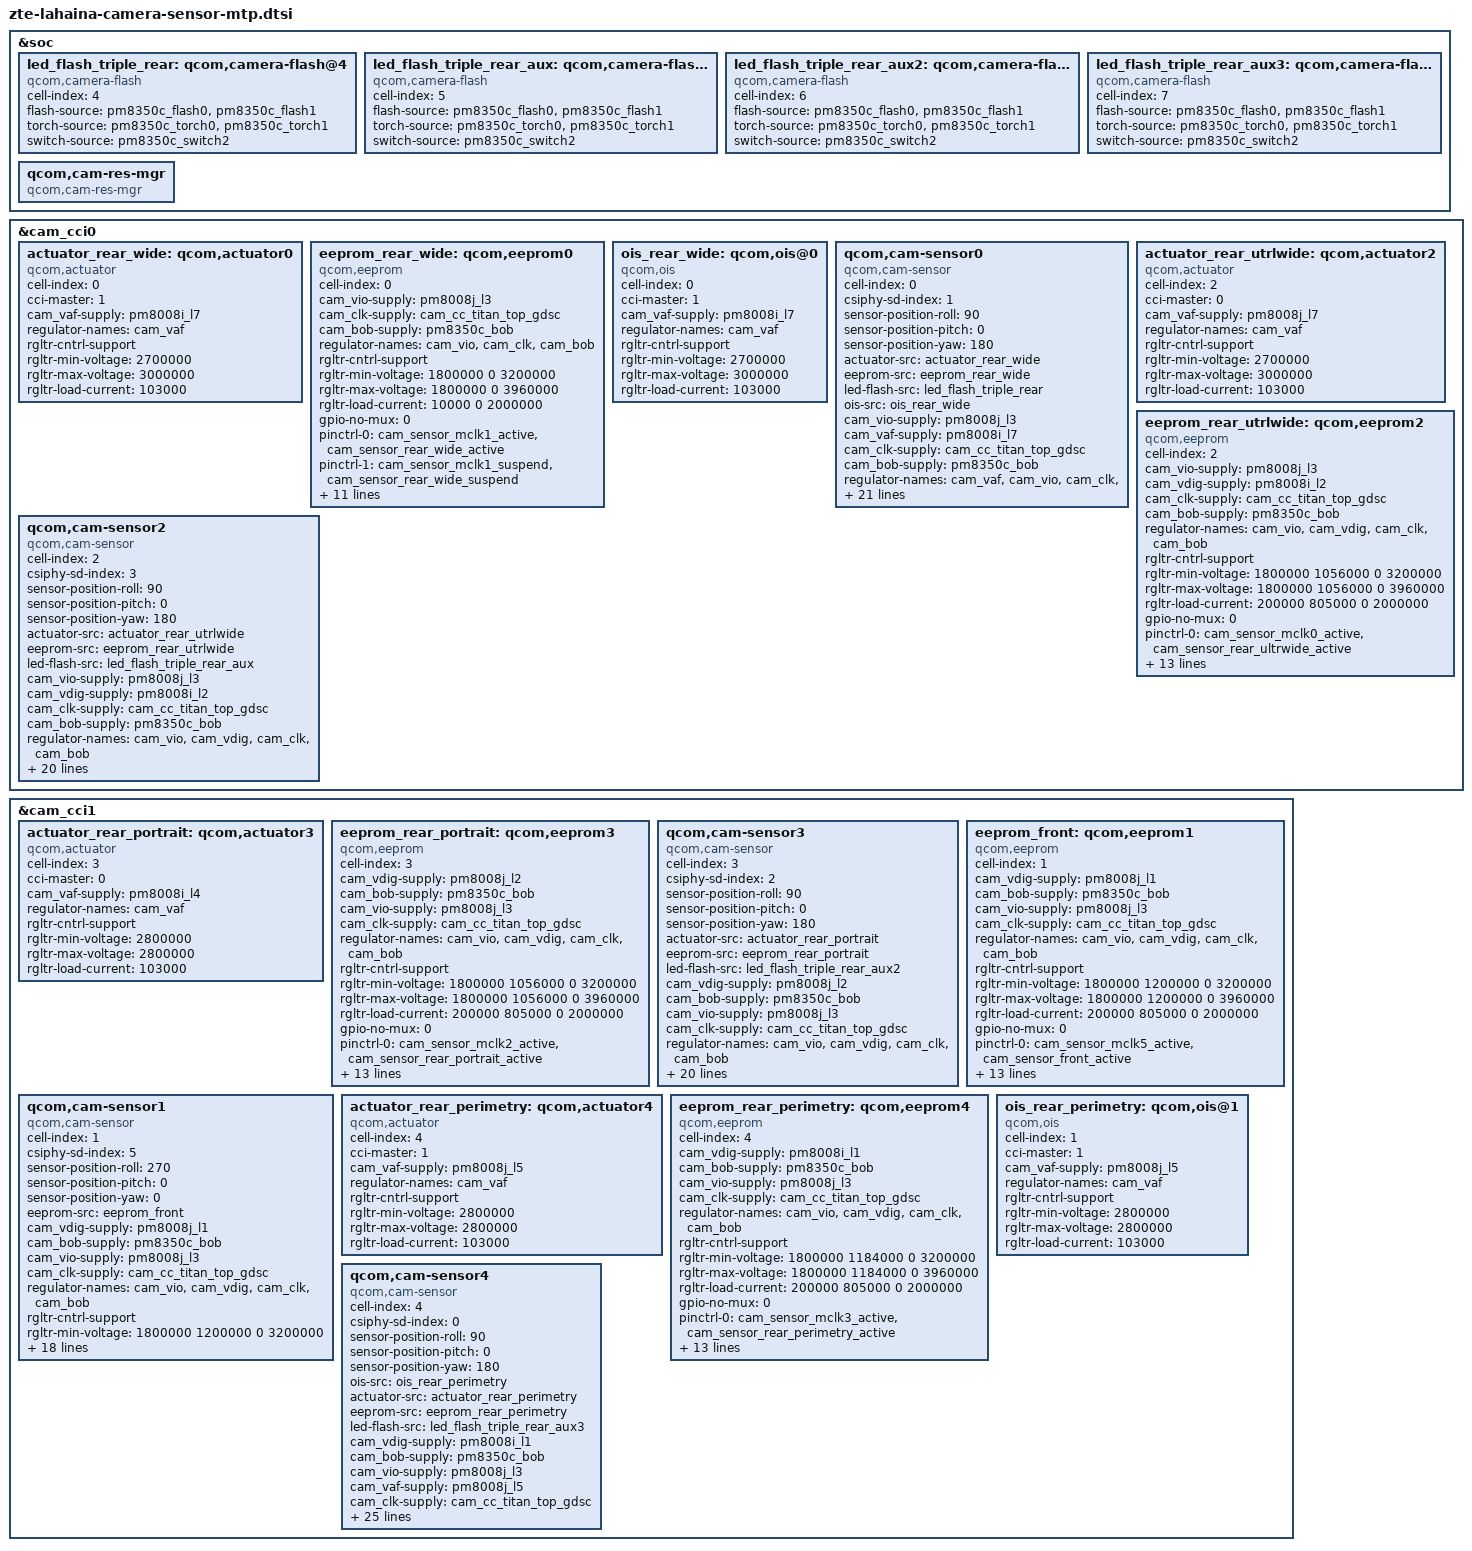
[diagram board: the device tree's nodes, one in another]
#include <dt-bindings/clock/qcom,camcc-lahaina.h>

&soc {
	led_flash_triple_rear: qcom,camera-flash@4 {
		cell-index = <4>;
		compatible = "qcom,camera-flash";
		flash-source = <&pm8350c_flash0 &pm8350c_flash1>;
		torch-source = <&pm8350c_torch0 &pm8350c_torch1>;
		switch-source = <&pm8350c_switch2>;
		status = "ok";
	};

	led_flash_triple_rear_aux: qcom,camera-flash@5 {
		cell-index = <5>;
		compatible = "qcom,camera-flash";
		flash-source = <&pm8350c_flash0 &pm8350c_flash1>;
		torch-source = <&pm8350c_torch0 &pm8350c_torch1>;
		switch-source = <&pm8350c_switch2>;
		status = "ok";
	};

	led_flash_triple_rear_aux2: qcom,camera-flash@6 {
		cell-index = <6>;
		compatible = "qcom,camera-flash";
		flash-source = <&pm8350c_flash0 &pm8350c_flash1>;
		torch-source = <&pm8350c_torch0 &pm8350c_torch1>;
		switch-source = <&pm8350c_switch2>;
		status = "ok";
	};

	led_flash_triple_rear_aux3: qcom,camera-flash@7 {
		cell-index = <7>;
		compatible = "qcom,camera-flash";
		flash-source = <&pm8350c_flash0 &pm8350c_flash1>;
		torch-source = <&pm8350c_torch0 &pm8350c_torch1>;
		switch-source = <&pm8350c_switch2>;
		status = "ok";
	};

	qcom,cam-res-mgr {
		compatible = "qcom,cam-res-mgr";
		status = "ok";
	};
};

&cam_cci0 {
	actuator_rear_wide: qcom,actuator0 {
		cell-index = <0>;
		compatible = "qcom,actuator";
		cci-master = <1>;
		cam_vaf-supply = <&pm8008i_l7>;
		regulator-names = "cam_vaf";
		rgltr-cntrl-support;
		rgltr-min-voltage = <2700000>;
		rgltr-max-voltage = <3000000>;
		rgltr-load-current = <103000>;
	};

	eeprom_rear_wide: qcom,eeprom0 {
		cell-index = <0>;
		compatible = "qcom,eeprom";
		cam_vio-supply = <&pm8008j_l3>;
		cam_clk-supply = <&cam_cc_titan_top_gdsc>;
		cam_bob-supply = <&pm8350c_bob>;
		regulator-names = "cam_vio", "cam_clk", "cam_bob";
		rgltr-cntrl-support;
		rgltr-min-voltage = <1800000 0 3200000>;
		rgltr-max-voltage = <1800000 0 3960000>;
		rgltr-load-current = <10000 0 2000000>;
		gpio-no-mux = <0>;
		pinctrl-names = "cam_default", "cam_suspend";
		pinctrl-0 = <&cam_sensor_mclk1_active
				 &cam_sensor_rear_wide_active>;
		pinctrl-1 = <&cam_sensor_mclk1_suspend
				 &cam_sensor_rear_wide_suspend>;
		gpios = <&tlmm 101 0>,
			<&tlmm 16 0>,
			<&tlmm 124 0>;
		gpio-reset = <1>;
		gpio-custom1 = <2>;
		gpio-req-tbl-num = <0 1 2>;
		gpio-req-tbl-flags = <1 0 0>;
		gpio-req-tbl-label = "CAMIF_MCLK1",
					"CAM_RESET0",
					"CAM_AVDD0";
		cci-master = <1>;
		status = "ok";
		clocks = <&clock_camcc CAM_CC_MCLK1_CLK>;
		clock-names = "cam_clk";
		clock-cntl-level = "nominal";
		clock-rates = <24000000>;
	};

	ois_rear_wide: qcom,ois@0 {
		cell-index = <0>;
		compatible = "qcom,ois";
		cci-master = <1>;
		cam_vaf-supply = <&pm8008i_l7>;
		regulator-names = "cam_vaf";
		rgltr-cntrl-support;
		rgltr-min-voltage = <2700000>;
		rgltr-max-voltage = <3000000>;
		rgltr-load-current = <103000>;
	};

	qcom,cam-sensor0 {
		cell-index = <0>;
		compatible = "qcom,cam-sensor";
		csiphy-sd-index = <1>;
		sensor-position-roll = <90>;
		sensor-position-pitch = <0>;
		sensor-position-yaw = <180>;
		actuator-src = <&actuator_rear_wide>;
		eeprom-src = <&eeprom_rear_wide>;
		led-flash-src = <&led_flash_triple_rear>;
		ois-src = <&ois_rear_wide>;
		cam_vio-supply = <&pm8008j_l3>;
		cam_vaf-supply = <&pm8008i_l7>;
		cam_clk-supply = <&cam_cc_titan_top_gdsc>;
		cam_bob-supply = <&pm8350c_bob>;
		regulator-names = "cam_vaf", "cam_vio", "cam_clk",
			"cam_bob";
		rgltr-cntrl-support;
		rgltr-min-voltage = <2700000 1800000 0 3200000>;
		rgltr-max-voltage = <3000000 1800000 0 3960000>;
		rgltr-load-current = <103000 10000 0 2000000>;
		gpio-no-mux = <0>;
		pinctrl-names = "cam_default", "cam_suspend";
		pinctrl-0 = <&cam_sensor_mclk1_active
				&cam_sensor_rear_wide_active>;
		pinctrl-1 = <&cam_sensor_mclk1_suspend
				&cam_sensor_rear_wide_suspend>;
		gpios = <&tlmm 101 0>,
			<&tlmm 16 0>,
			<&tlmm 124 0>;
		gpio-reset = <1>;
		gpio-custom1 = <2>;
		gpio-req-tbl-num = <0 1 2>;
		gpio-req-tbl-flags = <1 0 0>;
		gpio-req-tbl-label = "CAMIF_MCLK1",
					"CAM_RESET0",
					"CAM_AVDD0";
		cci-master = <1>;
		status = "ok";
		clocks = <&clock_camcc CAM_CC_MCLK1_CLK>;
		clock-names = "cam_clk";
		clock-cntl-level = "nominal";
		clock-rates = <24000000>;
	};

	actuator_rear_utrlwide: qcom,actuator2 {
		cell-index = <2>;
		compatible = "qcom,actuator";
		cci-master = <0>;
		cam_vaf-supply = <&pm8008j_l7>;
		regulator-names = "cam_vaf";
		rgltr-cntrl-support;
		rgltr-min-voltage = <2700000>;
		rgltr-max-voltage = <3000000>;
		rgltr-load-current = <103000>;
	};

	eeprom_rear_utrlwide: qcom,eeprom2 {
		cell-index = <2>;
		compatible = "qcom,eeprom";
		cam_vio-supply = <&pm8008j_l3>;
		cam_vdig-supply = <&pm8008i_l2>;
		cam_clk-supply = <&cam_cc_titan_top_gdsc>;
		cam_bob-supply = <&pm8350c_bob>;
		regulator-names = "cam_vio", "cam_vdig", "cam_clk",
			"cam_bob";
		rgltr-cntrl-support;
		rgltr-min-voltage = <1800000 1056000 0 3200000>;
		rgltr-max-voltage = <1800000 1056000 0 3960000>;
		rgltr-load-current = <200000 805000 0 2000000>;
		gpio-no-mux = <0>;
		pinctrl-names = "cam_default", "cam_suspend";
		pinctrl-0 = <&cam_sensor_mclk0_active
				 &cam_sensor_rear_ultrwide_active>;
		pinctrl-1 = <&cam_sensor_mclk0_suspend
				 &cam_sensor_rear_ultrwide_suspend>;
		gpios = <&tlmm 100 0>,
			<&tlmm 17 0>,
			<&tlmm 27 0>;
		gpio-reset = <1>;
		gpio-custom1 = <2>;
		gpio-req-tbl-num = <0 1 2>;
		gpio-req-tbl-flags = <1 0 0>;
		gpio-req-tbl-label = "CAMIF_MCLK1",
					"CAM_RESET2",
					"CAM_AVDD2";
		cci-master = <0>;
		status = "ok";
		clocks = <&clock_camcc CAM_CC_MCLK0_CLK>;
		clock-names = "cam_clk";
		clock-cntl-level = "nominal";
		clock-rates = <24000000>;
	};

	qcom,cam-sensor2 {
		cell-index = <2>;
		compatible = "qcom,cam-sensor";
		csiphy-sd-index = <3>;
		sensor-position-roll = <90>;
		sensor-position-pitch = <0>;
		sensor-position-yaw = <180>;
		actuator-src = <&actuator_rear_utrlwide>;
		eeprom-src = <&eeprom_rear_utrlwide>;
		led-flash-src = <&led_flash_triple_rear_aux>;
		cam_vio-supply = <&pm8008j_l3>;
		cam_vdig-supply = <&pm8008i_l2>;
		cam_clk-supply = <&cam_cc_titan_top_gdsc>;
		cam_bob-supply = <&pm8350c_bob>;
		regulator-names = "cam_vio", "cam_vdig", "cam_clk",
			"cam_bob";
		rgltr-cntrl-support;
		rgltr-min-voltage = <1800000 1056000 0 3200000>;
		rgltr-max-voltage = <1800000 1056000 0 3960000>;
		rgltr-load-current = <200000 805000 0 2000000>;
		gpio-no-mux = <0>;
		pinctrl-names = "cam_default", "cam_suspend";
		pinctrl-0 = <&cam_sensor_mclk0_active
				 &cam_sensor_rear_ultrwide_active>;
		pinctrl-1 = <&cam_sensor_mclk0_suspend
				 &cam_sensor_rear_ultrwide_suspend>;
		gpios = <&tlmm 100 0>,
			<&tlmm 17 0>,
			<&tlmm 27 0>;
		gpio-reset = <1>;
		gpio-custom1 = <2>;
		gpio-req-tbl-num = <0 1 2>;
		gpio-req-tbl-flags = <1 0 0>;
		gpio-req-tbl-label = "CAMIF_MCLK1",
					"CAM_RESET2",
					"CAM_AVDD2";
		cci-master = <0>;
		status = "ok";
		clocks = <&clock_camcc CAM_CC_MCLK0_CLK>;
		clock-names = "cam_clk";
		clock-cntl-level = "nominal";
		clock-rates = <24000000>;
	};
};

&cam_cci1 {
	actuator_rear_portrait: qcom,actuator3 {
		cell-index = <3>;
		compatible = "qcom,actuator";
		cci-master = <0>;
		cam_vaf-supply = <&pm8008i_l4>;
		regulator-names = "cam_vaf";
		rgltr-cntrl-support;
		rgltr-min-voltage = <2800000>;
		rgltr-max-voltage = <2800000>;
		rgltr-load-current = <103000>;
	};

	eeprom_rear_portrait: qcom,eeprom3 {
		cell-index = <3>;
		compatible = "qcom,eeprom";
		cam_vdig-supply = <&pm8008j_l2>;
		cam_bob-supply = <&pm8350c_bob>;
		cam_vio-supply = <&pm8008j_l3>;
		cam_clk-supply = <&cam_cc_titan_top_gdsc>;
		regulator-names = "cam_vio", "cam_vdig", "cam_clk",
			"cam_bob";
		rgltr-cntrl-support;
		rgltr-min-voltage = <1800000 1056000 0 3200000>;
		rgltr-max-voltage = <1800000 1056000 0 3960000>;
		rgltr-load-current = <200000 805000 0 2000000>;
		gpio-no-mux = <0>;
		pinctrl-names = "cam_default", "cam_suspend";
		pinctrl-0 = <&cam_sensor_mclk2_active
			&cam_sensor_rear_portrait_active>;
		pinctrl-1 = <&cam_sensor_mclk2_suspend
			&cam_sensor_rear_portrait_suspend>;
		gpios = <&tlmm 102 0>,
			<&tlmm 106 0>,
			<&tlmm 131 0>;
		gpio-reset = <1>;
		gpio-custom1 = <2>;
		gpio-req-tbl-num = <0 1 2>;
		gpio-req-tbl-flags = <1 0 0>;
		gpio-req-tbl-label = "CAMIF_MCLK2",
					"CAM_RESET3",
					"CAM_AVDD3";
		cci-master = <0>;
		status = "ok";
		clocks = <&clock_camcc CAM_CC_MCLK2_CLK>;
		clock-names = "cam_clk";
		clock-cntl-level = "nominal";
		clock-rates = <24000000>;
	};

	qcom,cam-sensor3 {
		cell-index = <3>;
		compatible = "qcom,cam-sensor";
		csiphy-sd-index = <2>;
		sensor-position-roll = <90>;
		sensor-position-pitch = <0>;
		sensor-position-yaw = <180>;
		actuator-src = <&actuator_rear_portrait>;
		eeprom-src = <&eeprom_rear_portrait>;
		led-flash-src = <&led_flash_triple_rear_aux2>;
		cam_vdig-supply = <&pm8008j_l2>;
		cam_bob-supply = <&pm8350c_bob>;
		cam_vio-supply = <&pm8008j_l3>;
		cam_clk-supply = <&cam_cc_titan_top_gdsc>;
		regulator-names = "cam_vio", "cam_vdig",
			"cam_clk", "cam_bob";
		rgltr-cntrl-support;
		rgltr-min-voltage = <1800000 1056000 0 3200000>;
		rgltr-max-voltage = <1800000 1056000 0 3960000>;
		rgltr-load-current = <200000 805000 0 2000000>;
		gpio-no-mux = <0>;
		pinctrl-names = "cam_default", "cam_suspend";
		pinctrl-0 = <&cam_sensor_mclk2_active
				 &cam_sensor_rear_portrait_active>;
		pinctrl-1 = <&cam_sensor_mclk2_suspend
				 &cam_sensor_rear_portrait_suspend>;
		gpios = <&tlmm 102 0>,
			<&tlmm 106 0>,
			<&tlmm 131 0>;
		gpio-reset = <1>;
		gpio-custom1 = <2>;
		gpio-req-tbl-num = <0 1 2>;
		gpio-req-tbl-flags = <1 0 0>;
		gpio-req-tbl-label = "CAMIF_MCLK2",
					"CAM_RESET3",
					"CAM_AVDD3";
		cci-master = <0>;
		status = "ok";
		clocks = <&clock_camcc CAM_CC_MCLK2_CLK>;
		clock-names = "cam_clk";
		clock-cntl-level = "nominal";
		clock-rates = <24000000>;
	};

	eeprom_front: qcom,eeprom1 {
		cell-index = <1>;
		compatible = "qcom,eeprom";
		cam_vdig-supply = <&pm8008j_l1>;
		cam_bob-supply = <&pm8350c_bob>;
		cam_vio-supply = <&pm8008j_l3>;
		cam_clk-supply = <&cam_cc_titan_top_gdsc>;
		regulator-names = "cam_vio", "cam_vdig", "cam_clk",
			"cam_bob";
		rgltr-cntrl-support;
		rgltr-min-voltage = <1800000 1200000 0 3200000>;
		rgltr-max-voltage = <1800000 1200000 0 3960000>;
		rgltr-load-current = <200000 805000 0 2000000>;
		gpio-no-mux = <0>;
		pinctrl-names = "cam_default", "cam_suspend";
		pinctrl-0 = <&cam_sensor_mclk5_active
				 &cam_sensor_front_active>;
		pinctrl-1 = <&cam_sensor_mclk5_suspend
				 &cam_sensor_front_suspend>;
		gpios = <&tlmm 105 0>,
			<&tlmm 115 0>,
			<&tlmm 123 0>;
		gpio-reset = <1>;
		gpio-custom1 = <2>;
		gpio-req-tbl-num = <0 1 2>;
		gpio-req-tbl-flags = <1 0 0>;
		gpio-req-tbl-label = "CAMIF_MCLK5",
					"CAM_RESET1",
					"CAM_AVDD1";
		cci-master = <1>;
		status = "ok";
		clocks = <&clock_camcc CAM_CC_MCLK5_CLK>;
		clock-names = "cam_clk";
		clock-cntl-level = "nominal";
		clock-rates = <24000000>;
	};

	qcom,cam-sensor1 {
		cell-index = <1>;
		compatible = "qcom,cam-sensor";
		csiphy-sd-index = <5>;
		sensor-position-roll = <270>;
		sensor-position-pitch = <0>;
		sensor-position-yaw = <0>;
		eeprom-src = <&eeprom_front>;
		cam_vdig-supply = <&pm8008j_l1>;
		cam_bob-supply = <&pm8350c_bob>;
		cam_vio-supply = <&pm8008j_l3>;
		cam_clk-supply = <&cam_cc_titan_top_gdsc>;
		regulator-names = "cam_vio", "cam_vdig", "cam_clk",
			"cam_bob";
		rgltr-cntrl-support;
		rgltr-min-voltage = <1800000 1200000 0 3200000>;
		rgltr-max-voltage = <1800000 1200000 0 3960000>;
		rgltr-load-current = <200000 805000 0 2000000>;
		gpio-no-mux = <0>;
		pinctrl-names = "cam_default", "cam_suspend";
		pinctrl-0 = <&cam_sensor_mclk5_active
				 &cam_sensor_front_active>;
		pinctrl-1 = <&cam_sensor_mclk5_suspend
				 &cam_sensor_front_suspend>;
		gpios = <&tlmm 105 0>,
			<&tlmm 115 0>,
			<&tlmm 123 0>;
		gpio-reset = <1>;
		gpio-custom1 = <2>;
		gpio-req-tbl-num = <0 1 2>;
		gpio-req-tbl-flags = <1 0 0>;
		gpio-req-tbl-label = "CAMIF_MCLK5",
					"CAM_RESET1",
					"CAM_AVDD1";
		cci-master = <1>;
		status = "ok";
		clocks = <&clock_camcc CAM_CC_MCLK5_CLK>;
		clock-names = "cam_clk";
		clock-cntl-level = "nominal";
		clock-rates = <24000000>;
	};

	actuator_rear_perimetry: qcom,actuator4 {
		cell-index = <4>;
		compatible = "qcom,actuator";
		cci-master = <1>;
		cam_vaf-supply = <&pm8008j_l5>;
		regulator-names = "cam_vaf";
		rgltr-cntrl-support;
		rgltr-min-voltage = <2800000>;
		rgltr-max-voltage = <2800000>;
		rgltr-load-current = <103000>;
	};

	eeprom_rear_perimetry: qcom,eeprom4 {
		cell-index = <4>;
		compatible = "qcom,eeprom";
		cam_vdig-supply = <&pm8008i_l1>;
		cam_bob-supply = <&pm8350c_bob>;
		cam_vio-supply = <&pm8008j_l3>;
		cam_clk-supply = <&cam_cc_titan_top_gdsc>;
		regulator-names = "cam_vio", "cam_vdig", "cam_clk",
			"cam_bob";
		rgltr-cntrl-support;
		rgltr-min-voltage = <1800000 1184000 0 3200000>;
		rgltr-max-voltage = <1800000 1184000 0 3960000>;
		rgltr-load-current = <200000 805000 0 2000000>;
		gpio-no-mux = <0>;
		pinctrl-names = "cam_default", "cam_suspend";
		pinctrl-0 = <&cam_sensor_mclk3_active
				 &cam_sensor_rear_perimetry_active>;
		pinctrl-1 = <&cam_sensor_mclk3_suspend
				 &cam_sensor_rear_perimetry_suspend>;
		gpios = <&tlmm 103 0>,
			<&tlmm 117 0>,
			<&tlmm 132 0>;
		gpio-reset = <1>;
		gpio-custom1 = <2>;
		gpio-req-tbl-num = <0 1 2>;
		gpio-req-tbl-flags = <1 0 0>;
		gpio-req-tbl-label = "CAMIF_MCLK3",
					"CAM_RESET4",
					"CAM_AVDD4";
		cci-master = <1>;
		status = "ok";
		clocks = <&clock_camcc CAM_CC_MCLK3_CLK>;
		clock-names = "cam_clk";
		clock-cntl-level = "nominal";
		clock-rates = <24000000>;
	};

	ois_rear_perimetry: qcom,ois@1 {
		cell-index = <1>;
		compatible = "qcom,ois";
		cci-master = <1>;
		cam_vaf-supply = <&pm8008j_l5>;
		regulator-names = "cam_vaf";
		rgltr-cntrl-support;
		rgltr-min-voltage = <2800000>;
		rgltr-max-voltage = <2800000>;
		rgltr-load-current = <103000>;
	};

	qcom,cam-sensor4 {
		cell-index = <4>;
		compatible = "qcom,cam-sensor";
		csiphy-sd-index = <0>;
		sensor-position-roll = <90>;
		sensor-position-pitch = <0>;
		sensor-position-yaw = <180>;
		ois-src = <&ois_rear_perimetry>;
		actuator-src = <&actuator_rear_perimetry>;
		eeprom-src = <&eeprom_rear_perimetry>;
		led-flash-src = <&led_flash_triple_rear_aux3>;
		cam_vdig-supply = <&pm8008i_l1>;
		cam_bob-supply = <&pm8350c_bob>;
		cam_vio-supply = <&pm8008j_l3>;
		cam_vaf-supply = <&pm8008j_l5>;
		cam_clk-supply = <&cam_cc_titan_top_gdsc>;
		regulator-names = "cam_vaf", "cam_vio", "cam_vdig",
			"cam_clk", "cam_bob";
		rgltr-cntrl-support;
		rgltr-min-voltage = <2800000 1800000 1176000 0 3200000>;
		rgltr-max-voltage = <2800000 1800000 1176000 0 3960000>;
		rgltr-load-current = <103000 200000 805000 0 2000000>;
		gpio-no-mux = <0>;
		pinctrl-names = "cam_default", "cam_suspend";
		pinctrl-0 = <&cam_sensor_mclk3_active
				 &cam_sensor_rear_perimetry_active>;
		pinctrl-1 = <&cam_sensor_mclk3_suspend
				 &cam_sensor_rear_perimetry_suspend>;
		gpios = <&tlmm 103 0>,
			<&tlmm 117 0>,
			<&tlmm 132 0>;
		gpio-reset = <1>;
		gpio-custom1 = <2>;
		gpio-req-tbl-num = <0 1 2>;
		gpio-req-tbl-flags = <1 0 0>;
		gpio-req-tbl-label = "CAMIF_MCLK3",
					"CAM_RESET4",
					"CAM_AVDD4";
		cci-master = <1>;
		status = "ok";
		clocks = <&clock_camcc CAM_CC_MCLK3_CLK>;
		clock-names = "cam_clk";
		clock-cntl-level = "nominal";
		clock-rates = <24000000>;
	};
};
